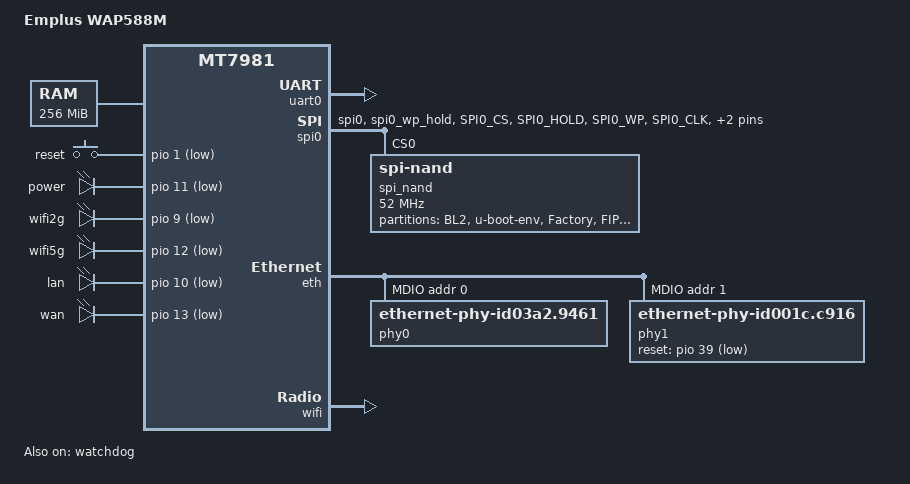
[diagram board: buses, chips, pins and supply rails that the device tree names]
// SPDX-License-Identifier: GPL-2.0-or-later OR MIT

/dts-v1/;
#include <dt-bindings/gpio/gpio.h>
#include <dt-bindings/input/input.h>
#include <dt-bindings/leds/common.h>

#include "mt7981.dtsi"

/ {
	model = "Emplus WAP588M";
	compatible = "emplus,wap588m", "mediatek,mt7981";
	chosen {
		bootargs = "console=ttyS0,115200n1 loglevel=8  \
				earlycon=uart8250,mmio32,0x11002000";
	};

	memory {
		reg = <0 0x40000000 0 0x10000000>;
	};

	gpio-keys {
		compatible = "gpio-keys";

		reset {
			label = "reset";
			linux,code = <KEY_RESTART>;
			gpios = <&pio 1 GPIO_ACTIVE_LOW>;
		};
	};

	leds {
		compatible = "gpio-leds";
		power {
			label = "power";
			gpios = <&pio 11 GPIO_ACTIVE_LOW>;
			linux,default-trigger = "timer";
			default-state = "on";

		};
		wifi2g {
			label = "wifi2g";
			gpios = <&pio 9 GPIO_ACTIVE_LOW>;
			linux,default-trigger = "ra0";
		};
		wifi5g {
			label = "wifi5g";
			gpios = <&pio 12 GPIO_ACTIVE_LOW>;
			linux,default-trigger = "rax0";
		};
		lan {
			label = "lan";
			gpios = <&pio 10 GPIO_ACTIVE_LOW>;
			linux,default-trigger = "eth0";
		};
		wan {
			label = "wan";
			gpios = <&pio 13 GPIO_ACTIVE_LOW>;
			linux,default-trigger = "eth1";
		};

	};
};





&pio {
	spi0_flash_pins: spi0-pins {
		mux {
			function = "spi";
			groups = "spi0", "spi0_wp_hold";
		};

		conf-pu {
			pins = "SPI0_CS", "SPI0_HOLD", "SPI0_WP";
			drive-strength = <MTK_DRIVE_8mA>;
			bias-pull-up = <MTK_PUPD_SET_R1R0_11>;
		};

		conf-pd {
			pins = "SPI0_CLK", "SPI0_MOSI", "SPI0_MISO";
			drive-strength = <MTK_DRIVE_8mA>;
			bias-pull-down = <MTK_PUPD_SET_R1R0_11>;
		};
	};
};

&uart0 {
	status = "okay";
};

&watchdog {
	status = "okay";
};

&spi0 {
	pinctrl-names = "default";
	pinctrl-0 = <&spi0_flash_pins>;
	status = "okay";

	spi_nand@0 {
		compatible = "spi-nand";
		#address-cells = <1>;
		#size-cells = <1>;
		reg = <0>;

		spi-max-frequency = <52000000>;
		spi-tx-bus-width = <4>;
		spi-rx-bus-width = <4>;

		mediatek,nmbm;
		mediatek,bmt-max-ratio = <1>;
		mediatek,bmt-max-reserved-blocks = <64>;

		partitions {
			compatible = "fixed-partitions";
			#address-cells = <1>;
			#size-cells = <1>;

			partition@0 {
				label = "BL2";
				reg = <0x0000000 0x0100000>;
				read-only;
			};

			partition@100000 {
				label = "u-boot-env";
				reg = <0x0100000 0x0080000>;
			};

			factory: partition@180000 {
				label = "Factory";
				reg = <0x180000 0x0200000>;
				read-only;

				nvmem-layout {
					compatible = "fixed-layout";
					#address-cells = <1>;
					#size-cells = <1>;

					eeprom_factory: eeprom@0 {
						reg = <0x0 0x1000>;
					};

					macaddr_wan: macaddr@2a {
						reg = <0x2a 0x6>;
					};

					macaddr_lan: macaddr@24 {
						reg = <0x24 0x6>;
					};
				};
			};

			partition@380000 {
				label = "FIP";
				reg = <0x380000 0x0200000>;
			};

			partition@580000 {
				label = "ubi"; //110MB
				reg = <0x580000 0x3700000>;
			};

			partition@3C80000 {
				label = "ubi_1"; //110MB
				reg = <0x3C80000 0x3700000>;
			};

			partition@7380000 {
				label = "cert"; //384KB
				reg = <0x7380000 0x0060000>;
			};

			partition@73E0000 {
				label = "userconfig"; //640KB
				reg = <0x73E0000 0x00a0000>;
			};

			partition@7480000 {
				label = "crashdump"; //384KB
				reg = <0x7480000 0x0060000>;
			};
		};
	};
};

&eth {
        status = "okay";

        gmac0: mac@0 {
                compatible = "mediatek,eth-mac";
                reg = <0>;
                phy-mode = "sgmii";
                phy-handle = <&phy1>;
        };

	gmac1: mac@1 {
		compatible = "mediatek,eth-mac";
		reg = <1>;
		phy-mode = "gmii";
		phy-handle = <&phy0>;
	};

        mdio: mdio-bus {
                #address-cells = <1>;
                #size-cells = <0>;

		// MT7981 internal PHY
		phy0: ethernet-phy@0 {
			compatible = "ethernet-phy-id03a2.9461";
			reg = <0>;
			phy-mode = "gmii";
			nvmem-cells = <&phy_calibration>;
			nvmem-cell-names = "phy-cal-data";
		};


		// RTL8211FS PHY
		phy1: ethernet-phy@1 {
			compatible = "ethernet-phy-id001c.c916";
			reg = <1>;
			reset-gpios = <&pio 39 GPIO_ACTIVE_LOW>;
			reset-assert-us = <120000>;
			reset-deassert-us = <120000>;
			phy-mode = "sgmii";
		};
    };
};

&wifi {
	status = "okay";

	mediatek,mtd-eeprom = <&factory 0x0>;
};
